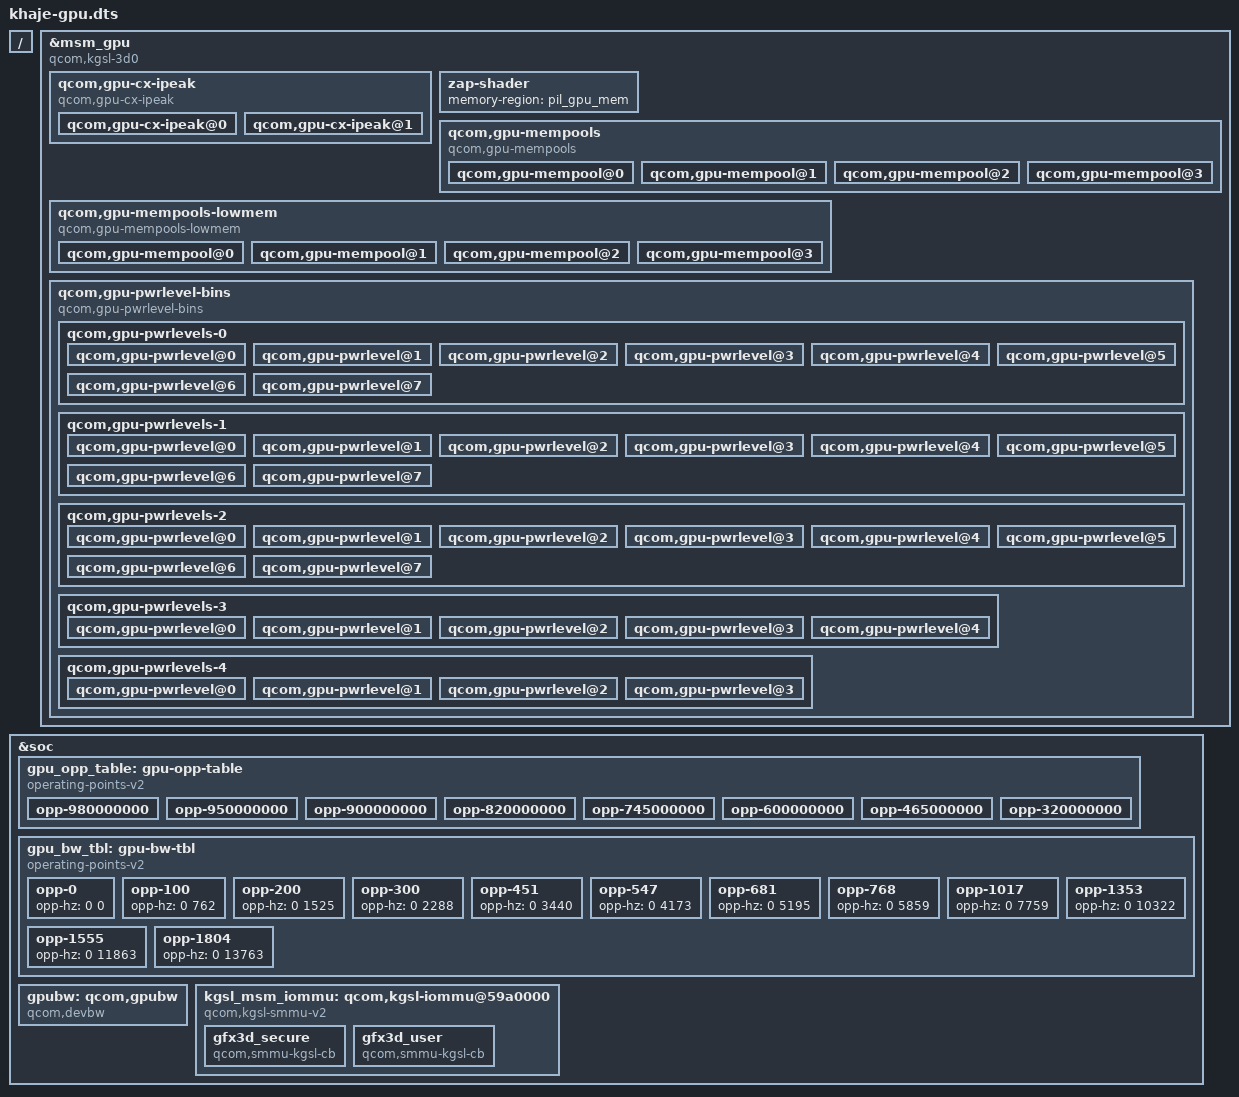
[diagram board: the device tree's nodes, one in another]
// SPDX-License-Identifier: GPL-2.0-only
/*
 * khaje GPU (Adreno 610, kgsl) base overlay
 *
 * Reconstructed from the stock Redmi Note 13 4G (sapphire) vendor_boot DTB
 * (HyperOS OS2.0.215.0.VNHEUXM): the Qualcomm "graphics-devicetree" techpack
 * devicetree is not published, so this overlay was rebuilt from the nodes
 * and properties it contributes to the merged khaje base DTB.  It is applied
 * onto qcom/khaje.dtb with fdtoverlay, as kernel_platform merge_dtbs.py does.
 */

/dts-v1/;
/plugin/;

#include <dt-bindings/clock/qcom,gcc-khaje.h>
#include <dt-bindings/clock/qcom,gpucc-khaje.h>
#include <dt-bindings/clock/qcom,rpmcc.h>
#include <dt-bindings/interconnect/qcom,bengal.h>
#include <dt-bindings/interrupt-controller/arm-gic.h>

/ {
	qcom,msm-id = <518 0x10000>, <586 0x10000>;
	qcom,board-id = <0 0>;
};

&msm_gpu {
	nvmem-cell-names = "speed_bin", "gaming_bin";
	nvmem-cells = <&gpu_speed_bin &gpu_gaming_bin>;
	qcom,ca-target-pwrlevel = <5>;
	qcom,ca-busy-penalty = <12000>;
	qcom,enable-ca-jump;
	qcom,pm-qos-wakeup-latency = <422>;
	qcom,pm-qos-active-latency = <422>;
	vdd-supply = <&gpu_gx_gdsc>;
	vddcx-supply = <&gpu_cx_gdsc>;
	regulator-names = "vddcx", "vdd";
	qcom,bus-table-ddr = <0 1562500 4273437 6000000 7945312 12148437 14093750 16343750>;
	qcom,bus-table-cnoc = <0 100>;
	interconnect-names = "gpu_icc_path";
	interconnects = <&bimc MASTER_GRAPHICS_3D &bimc SLAVE_EBI_CH0>;
	clock-names = "core_clk", "rbbmtimer_clk", "iface_clk", "ahb_clk", "mem_clk", "gmu_clk", "smmu_vote", "apb_pclk", "gpu_cc_ahb", "gcc_gpu_memnoc_gfx", "gpu_cc_hlos1_vote_gpu_smmu", "gcc_gpu_snoc_dvm_gfx";
	clocks = <&gpucc GPU_CC_GX_GFX3D_CLK &gpucc GPU_CC_CXO_CLK
	          &gcc GCC_BIMC_GPU_AXI_CLK &gpucc GPU_CC_AHB_CLK
	          &gcc GCC_GPU_MEMNOC_GFX_CLK &gpucc GPU_CC_CX_GMU_CLK
	          &gpucc GPU_CC_HLOS1_VOTE_GPU_SMMU_CLK &rpmcc RPM_QDSS_CLK
	          &gpucc GPU_CC_AHB_CLK &gcc GCC_GPU_MEMNOC_GFX_CLK
	          &gpucc GPU_CC_HLOS1_VOTE_GPU_SMMU_CLK &gcc GCC_GPU_SNOC_DVM_GFX_CLK>;
	#cooling-cells = <2>;
	qcom,gpu-qdss-stm = <0xe1c0000 0x40000>;
	qcom,min-access-length = <64>;
	qcom,ubwc-mode = <1>;
	qcom,initial-pwrlevel = <6>;
	qcom,chipid = <100728833>;
	qcom,gpu-model = "Adreno610v2";
	qcom,id = <0>;
	interrupt-names = "kgsl_3d0_irq";
	interrupts = <GIC_SPI 177 IRQ_TYPE_LEVEL_HIGH>;
	reg-names = "kgsl_3d0_reg_memory", "cx_dbgc";
	reg = <0x5900000 0x90000 0x5961000 0x800>;
	status = "ok";
	compatible = "qcom,kgsl-3d0", "qcom,kgsl-3d";
	label = "kgsl-3d0";
	qcom,gpu-cx-ipeak {
		compatible = "qcom,gpu-cx-ipeak";
		#size-cells = <0>;
		#address-cells = <1>;
		qcom,gpu-cx-ipeak@0 {
			qcom,gpu-cx-ipeak-freq = <950000000>;
			qcom,gpu-cx-ipeak = <&cx_ipeak_lm 10>;
		};
		qcom,gpu-cx-ipeak@1 {
			qcom,gpu-cx-ipeak-freq = <900000000>;
			qcom,gpu-cx-ipeak = <&cx_ipeak_lm 1>;
		};
	};
	zap-shader {
		memory-region = <&pil_gpu_mem>;
	};
	qcom,gpu-mempools {
		compatible = "qcom,gpu-mempools";
		#size-cells = <0>;
		#address-cells = <1>;
		qcom,gpu-mempool@0 {
			qcom,mempool-allocate;
			qcom,mempool-page-size = <4096>;
			reg = <0x0>;
		};
		qcom,gpu-mempool@1 {
			qcom,mempool-allocate;
			qcom,mempool-page-size = <8192>;
			reg = <0x1>;
		};
		qcom,gpu-mempool@2 {
			qcom,mempool-reserved = <256>;
			qcom,mempool-page-size = <0x10000>;
			reg = <0x2>;
		};
		qcom,gpu-mempool@3 {
			qcom,mempool-reserved = <32>;
			qcom,mempool-page-size = <0x100000>;
			reg = <0x3>;
		};
	};
	qcom,gpu-mempools-lowmem {
		compatible = "qcom,gpu-mempools-lowmem";
		#size-cells = <0>;
		#address-cells = <1>;
		qcom,gpu-mempool@0 {
			qcom,mempool-allocate;
			qcom,mempool-page-size = <4096>;
			reg = <0x0>;
		};
		qcom,gpu-mempool@1 {
			qcom,mempool-allocate;
			qcom,mempool-page-size = <8192>;
			reg = <0x1>;
		};
		qcom,gpu-mempool@2 {
			qcom,mempool-max-pages = <256>;
			qcom,mempool-allocate;
			qcom,mempool-page-size = <0x10000>;
			reg = <0x2>;
		};
		qcom,gpu-mempool@3 {
			qcom,mempool-max-pages = <32>;
			qcom,mempool-allocate;
			qcom,mempool-page-size = <0x100000>;
			reg = <0x3>;
		};
	};
	qcom,gpu-pwrlevel-bins {
		compatible = "qcom,gpu-pwrlevel-bins";
		#size-cells = <0>;
		#address-cells = <1>;
		qcom,gpu-pwrlevels-0 {
			qcom,ca-target-pwrlevel = <5>;
			qcom,initial-pwrlevel = <6>;
			qcom,speed-bin = <0>;
			#size-cells = <0>;
			#address-cells = <1>;
			qcom,gpu-pwrlevel@0 {
				qcom,level = <416>;
				qcom,bus-max = <7>;
				qcom,bus-min = <7>;
				qcom,bus-freq = <7>;
				qcom,gpu-freq = <1260000000>;
				reg = <0x0>;
			};
			qcom,gpu-pwrlevel@1 {
				qcom,level = <416>;
				qcom,bus-max = <7>;
				qcom,bus-min = <7>;
				qcom,bus-freq = <7>;
				qcom,gpu-freq = <1114800000>;
				reg = <0x1>;
			};
			qcom,gpu-pwrlevel@2 {
				qcom,level = <384>;
				qcom,bus-max = <7>;
				qcom,bus-min = <5>;
				qcom,bus-freq = <6>;
				qcom,gpu-freq = <1025000000>;
				reg = <0x2>;
			};
			qcom,gpu-pwrlevel@3 {
				qcom,level = <256>;
				qcom,bus-max = <5>;
				qcom,bus-min = <4>;
				qcom,bus-freq = <5>;
				qcom,gpu-freq = <785000000>;
				reg = <0x3>;
			};
			qcom,gpu-pwrlevel@4 {
				qcom,level = <192>;
				qcom,bus-max = <5>;
				qcom,bus-min = <3>;
				qcom,bus-freq = <4>;
				qcom,gpu-freq = <600000000>;
				reg = <0x4>;
			};
			qcom,gpu-pwrlevel@5 {
				qcom,level = <128>;
				qcom,bus-max = <4>;
				qcom,bus-min = <2>;
				qcom,bus-freq = <3>;
				qcom,gpu-freq = <465000000>;
				reg = <0x5>;
			};
			qcom,gpu-pwrlevel@6 {
				qcom,level = <64>;
				qcom,bus-max = <2>;
				qcom,bus-min = <1>;
				qcom,bus-freq = <2>;
				qcom,gpu-freq = <0x1312d000>;
				reg = <0x6>;
			};
			qcom,gpu-pwrlevel@7 {
				qcom,level = <64>;
				qcom,bus-max = <0>;
				qcom,bus-min = <0>;
				qcom,bus-freq = <0>;
				qcom,gpu-freq = <0>;
				reg = <0x7>;
			};
		};
		qcom,gpu-pwrlevels-1 {
			qcom,ca-target-pwrlevel = <4>;
			qcom,initial-pwrlevel = <5>;
			qcom,speed-bin = <235>;
			#size-cells = <0>;
			#address-cells = <1>;
			qcom,gpu-pwrlevel@0 {
				qcom,level = <416>;
				qcom,bus-max = <7>;
				qcom,bus-min = <7>;
				qcom,bus-freq = <7>;
				qcom,gpu-freq = <1114800000>;
				reg = <0x0>;
			};
			qcom,gpu-pwrlevel@1 {
				qcom,level = <384>;
				qcom,bus-max = <7>;
				qcom,bus-min = <5>;
				qcom,bus-freq = <6>;
				qcom,gpu-freq = <1025000000>;
				reg = <0x1>;
			};
			qcom,gpu-pwrlevel@2 {
				qcom,level = <256>;
				qcom,bus-max = <5>;
				qcom,bus-min = <4>;
				qcom,bus-freq = <5>;
				qcom,gpu-freq = <785000000>;
				reg = <0x2>;
			};
			qcom,gpu-pwrlevel@3 {
				qcom,level = <192>;
				qcom,bus-max = <5>;
				qcom,bus-min = <3>;
				qcom,bus-freq = <4>;
				qcom,gpu-freq = <600000000>;
				reg = <0x3>;
			};
			qcom,gpu-pwrlevel@4 {
				qcom,level = <128>;
				qcom,bus-max = <4>;
				qcom,bus-min = <2>;
				qcom,bus-freq = <3>;
				qcom,gpu-freq = <465000000>;
				reg = <0x4>;
			};
			qcom,gpu-pwrlevel@5 {
				qcom,level = <64>;
				qcom,bus-max = <2>;
				qcom,bus-min = <1>;
				qcom,bus-freq = <2>;
				qcom,gpu-freq = <0x1312d000>;
				reg = <0x5>;
			};
			qcom,gpu-pwrlevel@6 {
				qcom,level = <64>;
				qcom,bus-max = <0>;
				qcom,bus-min = <0>;
				qcom,bus-freq = <0>;
				qcom,gpu-freq = <0>;
				reg = <0x6>;
			};
			qcom,gpu-pwrlevel@7 {
				qcom,level = <64>;
				qcom,bus-max = <0>;
				qcom,bus-min = <0>;
				qcom,bus-freq = <0>;
				qcom,gpu-freq = <0>;
				reg = <0x7>;
			};
		};
		qcom,gpu-pwrlevels-2 {
			qcom,ca-target-pwrlevel = <3>;
			qcom,initial-pwrlevel = <4>;
			qcom,speed-bin = <216>;
			#size-cells = <0>;
			#address-cells = <1>;
			qcom,gpu-pwrlevel@0 {
				qcom,level = <384>;
				qcom,bus-max = <7>;
				qcom,bus-min = <5>;
				qcom,bus-freq = <6>;
				qcom,gpu-freq = <1025000000>;
				reg = <0x0>;
			};
			qcom,gpu-pwrlevel@1 {
				qcom,level = <256>;
				qcom,bus-max = <5>;
				qcom,bus-min = <4>;
				qcom,bus-freq = <5>;
				qcom,gpu-freq = <785000000>;
				reg = <0x1>;
			};
			qcom,gpu-pwrlevel@2 {
				qcom,level = <192>;
				qcom,bus-max = <5>;
				qcom,bus-min = <3>;
				qcom,bus-freq = <4>;
				qcom,gpu-freq = <600000000>;
				reg = <0x2>;
			};
			qcom,gpu-pwrlevel@3 {
				qcom,level = <128>;
				qcom,bus-max = <4>;
				qcom,bus-min = <2>;
				qcom,bus-freq = <3>;
				qcom,gpu-freq = <465000000>;
				reg = <0x3>;
			};
			qcom,gpu-pwrlevel@4 {
				qcom,level = <64>;
				qcom,bus-max = <2>;
				qcom,bus-min = <1>;
				qcom,bus-freq = <2>;
				qcom,gpu-freq = <0x1312d000>;
				reg = <0x4>;
			};
			qcom,gpu-pwrlevel@5 {
				qcom,level = <64>;
				qcom,bus-max = <0>;
				qcom,bus-min = <0>;
				qcom,bus-freq = <0>;
				qcom,gpu-freq = <0>;
				reg = <0x5>;
			};
			qcom,gpu-pwrlevel@6 {
				qcom,level = <64>;
				qcom,bus-max = <5>;
				qcom,bus-min = <3>;
				qcom,bus-freq = <4>;
				qcom,gpu-freq = <0x1312d000>;
				reg = <0x6>;
			};
			qcom,gpu-pwrlevel@7 {
				qcom,level = <64>;
				qcom,bus-max = <0>;
				qcom,bus-min = <0>;
				qcom,bus-freq = <0>;
				qcom,gpu-freq = <0>;
				reg = <0x7>;
			};
		};
		qcom,gpu-pwrlevels-3 {
			qcom,ca-target-pwrlevel = <2>;
			qcom,initial-pwrlevel = <3>;
			qcom,speed-bin = <157>;
			#size-cells = <0>;
			#address-cells = <1>;
			qcom,gpu-pwrlevel@0 {
				qcom,level = <256>;
				qcom,bus-max = <11>;
				qcom,bus-min = <9>;
				qcom,bus-freq = <11>;
				qcom,gpu-freq = <745000000>;
				reg = <0x0>;
			};
			qcom,gpu-pwrlevel@1 {
				qcom,level = <192>;
				qcom,bus-max = <10>;
				qcom,bus-min = <8>;
				qcom,bus-freq = <8>;
				qcom,gpu-freq = <600000000>;
				reg = <0x1>;
			};
			qcom,gpu-pwrlevel@2 {
				qcom,level = <128>;
				qcom,bus-max = <8>;
				qcom,bus-min = <5>;
				qcom,bus-freq = <7>;
				qcom,gpu-freq = <465000000>;
				reg = <0x2>;
			};
			qcom,gpu-pwrlevel@3 {
				qcom,level = <64>;
				qcom,bus-max = <5>;
				qcom,bus-min = <3>;
				qcom,bus-freq = <4>;
				qcom,gpu-freq = <0x1312d000>;
				reg = <0x3>;
			};
			qcom,gpu-pwrlevel@4 {
				qcom,level = <64>;
				qcom,bus-max = <0>;
				qcom,bus-min = <0>;
				qcom,bus-freq = <0>;
				qcom,gpu-freq = <0>;
				reg = <0x4>;
			};
		};
		qcom,gpu-pwrlevels-4 {
			qcom,ca-target-pwrlevel = <1>;
			qcom,initial-pwrlevel = <2>;
			qcom,speed-bin = <127>;
			#size-cells = <0>;
			#address-cells = <1>;
			qcom,gpu-pwrlevel@0 {
				qcom,level = <192>;
				qcom,bus-max = <11>;
				qcom,bus-min = <8>;
				qcom,bus-freq = <11>;
				qcom,gpu-freq = <600000000>;
				reg = <0x0>;
			};
			qcom,gpu-pwrlevel@1 {
				qcom,level = <128>;
				qcom,bus-max = <9>;
				qcom,bus-min = <5>;
				qcom,bus-freq = <7>;
				qcom,gpu-freq = <465000000>;
				reg = <0x1>;
			};
			qcom,gpu-pwrlevel@2 {
				qcom,level = <64>;
				qcom,bus-max = <5>;
				qcom,bus-min = <3>;
				qcom,bus-freq = <4>;
				qcom,gpu-freq = <0x1312d000>;
				reg = <0x2>;
			};
			qcom,gpu-pwrlevel@3 {
				qcom,level = <64>;
				qcom,bus-max = <0>;
				qcom,bus-min = <0>;
				qcom,bus-freq = <0>;
				qcom,gpu-freq = <0>;
				reg = <0x3>;
			};
		};
	};
};

&soc {
	gpu_opp_table: gpu-opp-table {
		compatible = "operating-points-v2";
		opp-980000000 {
			opp-microvolt = <416>;
			opp-hz = <0 980000000>;
		};
		opp-950000000 {
			opp-microvolt = <416>;
			opp-hz = <0 950000000>;
		};
		opp-900000000 {
			opp-microvolt = <384>;
			opp-hz = <0 900000000>;
		};
		opp-820000000 {
			opp-microvolt = <320>;
			opp-hz = <0 820000000>;
		};
		opp-745000000 {
			opp-microvolt = <256>;
			opp-hz = <0 745000000>;
		};
		opp-600000000 {
			opp-microvolt = <192>;
			opp-hz = <0 600000000>;
		};
		opp-465000000 {
			opp-microvolt = <128>;
			opp-hz = <0 465000000>;
		};
		opp-320000000 {
			opp-microvolt = <64>;
			opp-hz = <0 0x1312d000>;
		};
	};
	gpu_bw_tbl: gpu-bw-tbl {
		compatible = "operating-points-v2";
		opp-0 {
			opp-hz = <0 0>;
		};
		opp-100 {
			opp-hz = <0 762>;
		};
		opp-200 {
			opp-hz = <0 1525>;
		};
		opp-300 {
			opp-hz = <0 2288>;
		};
		opp-451 {
			opp-hz = <0 3440>;
		};
		opp-547 {
			opp-hz = <0 4173>;
		};
		opp-681 {
			opp-hz = <0 5195>;
		};
		opp-768 {
			opp-hz = <0 5859>;
		};
		opp-1017 {
			opp-hz = <0 7759>;
		};
		opp-1353 {
			opp-hz = <0 10322>;
		};
		opp-1555 {
			opp-hz = <0 11863>;
		};
		opp-1804 {
			opp-hz = <0 13763>;
		};
	};
	gpubw: qcom,gpubw {
		compatible = "qcom,devbw";
		governor = "bw_vbif";
		qcom,src-dst-ports = <26 512>;
		operating-points-v2 = <&gpu_bw_tbl>;
	};
	kgsl_msm_iommu: qcom,kgsl-iommu@59a0000 {
		compatible = "qcom,kgsl-smmu-v2";
		reg = <0x59a0000 0x10000>;
		qcom,protect = <0xa0000 0x10000>;
		vddcx-supply = <&gpu_cx_gdsc>;
		qcom,retention;
		qcom,hyp_secure_alloc;
		gfx3d_secure: gfx3d_secure {
			compatible = "qcom,smmu-kgsl-cb";
			label = "gfx3d_secure";
			iommus = <&kgsl_smmu 2 0>;
			qcom,iommu-dma = "disabled";
		};
		gfx3d_user: gfx3d_user {
			compatible = "qcom,smmu-kgsl-cb";
			label = "gfx3d_user";
			iommus = <&kgsl_smmu 0 1>;
			qcom,iommu-dma = "disabled";
			qcom,gpu-offset = <0xa8000>;
		};
	};
};
